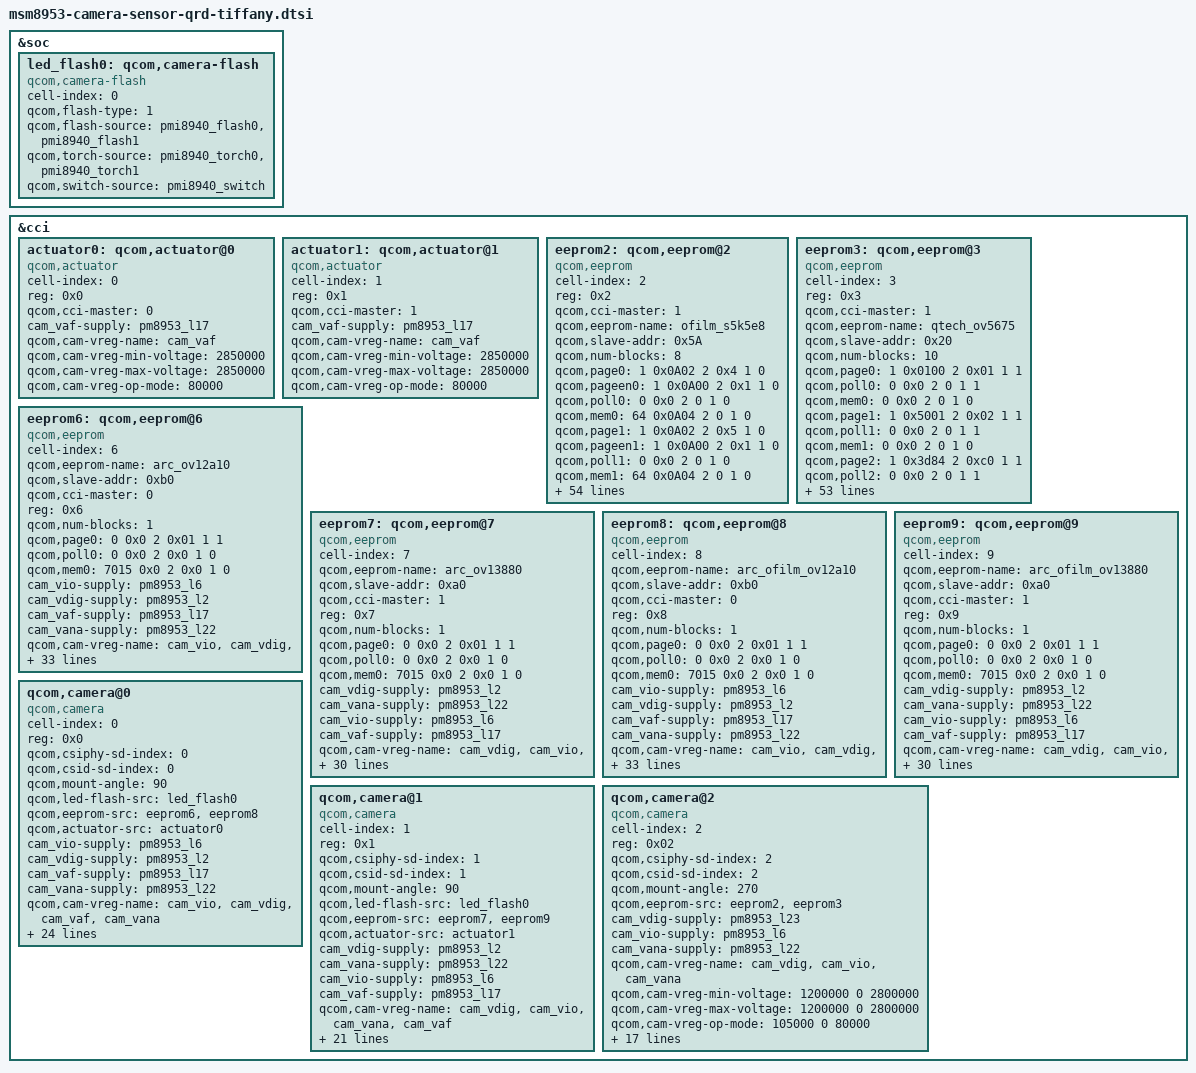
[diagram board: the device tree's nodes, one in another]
/*
 * Copyright (c) 2015-2016, The Linux Foundation. All rights reserved.
 * Copyright (C) 2019 XiaoMi, Inc.
 *
 * This program is free software; you can redistribute it and/or modify
 * it under the terms of the GNU General Public License version 2 and
 * only version 2 as published by the Free Software Foundation.
 *
 * This program is distributed in the hope that it will be useful,
 * but WITHOUT ANY WARRANTY; without even the implied warranty of
 * MERCHANTABILITY or FITNESS FOR A PARTICULAR PURPOSE.  See the
 * GNU General Public License for more details.
 */

&soc {
	led_flash0: qcom,camera-flash {
		cell-index = <0>;
		compatible = "qcom,camera-flash";
		qcom,flash-type = <1>;
		qcom,flash-source = <&pmi8940_flash0 &pmi8940_flash1>;
		qcom,torch-source = <&pmi8940_torch0 &pmi8940_torch1>;
		qcom,switch-source = <&pmi8940_switch>;
	};
};

&cci {
	actuator0: qcom,actuator@0 {
		cell-index = <0>;
		reg = <0x0>;
		compatible = "qcom,actuator";
		qcom,cci-master = <0>;
		cam_vaf-supply = <&pm8953_l17>;
		qcom,cam-vreg-name = "cam_vaf";
		qcom,cam-vreg-min-voltage = <2850000>;
		qcom,cam-vreg-max-voltage = <2850000>;
		qcom,cam-vreg-op-mode = <80000>;
	};

	actuator1: qcom,actuator@1 {
		cell-index = <1>;
		reg = <0x1>;
		compatible = "qcom,actuator";
		qcom,cci-master = <1>;
		cam_vaf-supply = <&pm8953_l17>;
		qcom,cam-vreg-name = "cam_vaf";
		qcom,cam-vreg-min-voltage = <2850000>;
		qcom,cam-vreg-max-voltage = <2850000>;
		qcom,cam-vreg-op-mode = <80000>;
	};


	eeprom2: qcom,eeprom@2 {
		cell-index = <2>;
		reg = <0x2>;
		compatible = "qcom,eeprom";
		qcom,cci-master = <1>;

		qcom,eeprom-name = "ofilm_s5k5e8";
		qcom,slave-addr = <0x5A>;
		qcom,num-blocks = <8>;

		qcom,page0 = <1 0x0A02 2 0x4 1 0>;
		qcom,pageen0 = <1 0x0A00 2 0x1 1 0>;
		qcom,poll0 = <0 0x0 2 0 1 0>;
		qcom,mem0 = <64 0x0A04 2 0 1 0>;

		qcom,page1 = <1 0x0A02 2 0x5 1 0>;
		qcom,pageen1 = <1 0x0A00 2 0x1 1 0>;
		qcom,poll1 = <0 0x0 2 0 1 0>;
		qcom,mem1 = <64 0x0A04 2 0 1 0>;

		qcom,page2 = <1 0x0A02 2 0x6 1 0>;
		qcom,pageen2 = <1 0x0A00 2 0x1 1 0>;
		qcom,poll2 = <0 0x0 2 0 1 0>;
		qcom,mem2 = <64 0x0A04 2 0 1 0>;

		qcom,page3 = <1 0x0A02 2 0x7 1 0>;
		qcom,pageen3 = <1 0x0A00 2 0x1 1 0>;
		qcom,poll3 = <0 0x0 2 0 1 0>;
		qcom,mem3 = <64 0x0A04 2 0 1 0>;

		qcom,page4 = <1 0x0A02 2 0x8 1 0>;
		qcom,pageen4 = <1 0x0A00 2 0x1 1 0>;
		qcom,poll4 = <0 0x0 2 0 1 0>;
		qcom,mem4 = <64 0x0A04 2 0 1 0>;

		qcom,page5 = <1 0x0A02 2 0x9 1 0>;
		qcom,pageen5 = <1 0x0A00 2 0x1 1 0>;
		qcom,poll5 = <0 0x0 2 0 1 0>;
		qcom,mem5 = <64 0x0A04 2 0 1 0>;

		qcom,page6 = <1 0x0A02 2 0xA 1 0>;
		qcom,pageen6 = <1 0x0A00 2 0x1 1 0>;
		qcom,poll6 = <0 0x0 2 0 1 0>;
		qcom,mem6 = <64 0x0A04 2 0 1 0>;

		qcom,page7 = <1 0x0A02 2 0xE 1 0>;
		qcom,pageen7 = <1 0x0A00 2 0x1 1 0>;
		qcom,poll7 = <0 0x0 2 0 1 0>;
		qcom,mem7 = <2 0x0A04 2 0 1 0>;

		cam_vdig-supply = <&pm8953_l23>;
		cam_vana-supply = <&pm8953_l22>;
		cam_vio-supply = <&pm8953_l6>;
		qcom,cam-vreg-name = "cam_vdig", "cam_vio", "cam_vana";
		qcom,cam-vreg-min-voltage = <1200000 0 2800000>;
		qcom,cam-vreg-max-voltage = <1200000 0 2800000>;
		qcom,cam-vreg-op-mode = <105000 0 80000>;
		qcom,gpio-no-mux = <0>;
		pinctrl-names = "cam_default", "cam_suspend";
		pinctrl-0 = <&cam_sensor_mclk1_default
						&cam_sensor_front1_default>;
		pinctrl-1 = <&cam_sensor_mclk1_sleep &cam_sensor_front1_sleep>;
		gpios = <&tlmm 27 0>,
			<&tlmm 129 0>;
		qcom,gpio-reset = <1>;
		qcom,gpio-req-tbl-num = <0 1>;
		qcom,gpio-req-tbl-flags = <1 0>;
		qcom,gpio-req-tbl-label = "CAMIF_MCLK2",
					  "CAM_RESET2";
		qcom,cam-power-seq-type = "sensor_gpio", "sensor_vreg",
			"sensor_vreg", "sensor_vreg", "sensor_clk" , "sensor_gpio";
		qcom,cam-power-seq-val = "sensor_gpio_reset", "cam_vana",
			"cam_vdig",	"cam_vio", "sensor_cam_mclk", "sensor_gpio_reset";
		qcom,cam-power-seq-cfg-val = <0 1 1 1 24000000 1>;
		qcom,cam-power-seq-delay = <1 0 0 0 10 1>;

		status = "ok";
		clocks = <&clock_gcc clk_mclk1_clk_src>,
			<&clock_gcc clk_gcc_camss_mclk1_clk>;
		clock-names = "cam_src_clk", "cam_clk";
		qcom,clock-rates = <24000000 0>;
	};


	eeprom3: qcom,eeprom@3 {
		cell-index = <3>;
		reg = <0x3>;
		compatible = "qcom,eeprom";
		qcom,cci-master = <1>;

		qcom,eeprom-name = "qtech_ov5675";
		qcom,slave-addr = <0x20>;

		qcom,num-blocks = <10>;
		qcom,page0 = <1 0x0100 2 0x01 1 1>;
		qcom,poll0 = <0 0x0 2 0 1 1>;
		qcom,mem0 = <0 0x0 2 0 1 0>;

		qcom,page1 = <1 0x5001 2 0x02 1 1>;
		qcom,poll1 = <0 0x0 2 0 1 1>;
		qcom,mem1 = <0 0x0 2 0 1 0>;

		qcom,page2 = <1 0x3d84 2 0xc0 1 1>;
		qcom,poll2 = <0 0x0 2 0 1 1>;
		qcom,mem2 = <0 0x0 2 0 1 0>;

		qcom,page3 = <1 0x3d88 2 0x70 1 1>;
		qcom,poll3 = <0 0x0 2 0 1 1>;
		qcom,mem3 = <0 0x0 2 0 1 0>;

		qcom,page4 = <1 0x3d89 2 0x10 1 1>;
		qcom,poll4 = <0 0x0 2 0 1 1>;
		qcom,mem4 = <0 0x0 2 0 1 0>;

		qcom,page5 = <1 0x3d8a 2 0x70 1 0>;
		qcom,poll5 = <0 0x0 2 0 1 1>;
		qcom,mem5 = <0 0x0 2 0 1 0>;

		qcom,page6 = <1 0x3d8b 2 0x29 1 10>;
		qcom,poll6 = <0 0x0 2 0 1 1>;
		qcom,mem6 = <0 0x0 2 0 1 0>;

		qcom,page7 = <1 0x3d81 2 0x01 1 10>;
		qcom,poll7 = <0 0x0 2 0 1 1>;
		qcom,mem7 = <0 0x0 2 0 1 0>;

		qcom,page8 = <0 0x0 2 0 1 0>;
		qcom,poll8 = <0 0x0 2 0 1 1>;
		qcom,mem8 = <40 0x7010 2 0 1 5>;

		qcom,page9 = <1 0x5001 2 0x03 1 5>;
		qcom,pageen9 = <1 0x0100 2 0x00 1 5>;
		qcom,poll9 = <0 0x0 2 0 1 1>;
		qcom,mem9 = <0 0x0 2 0 1 0>;

		cam_vdig-supply = <&pm8953_l23>;
		cam_vana-supply = <&pm8953_l22>;
		cam_vio-supply = <&pm8953_l6>;
		qcom,cam-vreg-name = "cam_vdig", "cam_vio", "cam_vana";
		qcom,cam-vreg-min-voltage = <1200000 0 2800000>;
		qcom,cam-vreg-max-voltage = <1200000 0 2800000>;
		qcom,cam-vreg-op-mode = <105000 0 80000>;
		qcom,gpio-no-mux = <0>;
		pinctrl-names = "cam_default", "cam_suspend";
		pinctrl-0 = <&cam_sensor_mclk1_default
						&cam_sensor_front1_default>;
		pinctrl-1 = <&cam_sensor_mclk1_sleep &cam_sensor_front1_sleep>;
		gpios = <&tlmm 27 0>,
			<&tlmm 129 0>;
		qcom,gpio-reset = <1>;
		qcom,gpio-req-tbl-num = <0 1>;
		qcom,gpio-req-tbl-flags = <1 0>;
		qcom,gpio-req-tbl-label = "CAMIF_MCLK2",
					  "CAM_RESET2";
		qcom,cam-power-seq-type = "sensor_gpio", "sensor_vreg",
			"sensor_vreg", "sensor_vreg", "sensor_clk" , "sensor_gpio";
		qcom,cam-power-seq-val = "sensor_gpio_reset", "cam_vana",
			"cam_vdig",	"cam_vio", "sensor_cam_mclk", "sensor_gpio_reset";
		qcom,cam-power-seq-cfg-val = <0 1 1 1 24000000 1>;
		qcom,cam-power-seq-delay = <1 0 0 0 10 1>;

		status = "ok";
		clocks = <&clock_gcc clk_mclk1_clk_src>,
			<&clock_gcc clk_gcc_camss_mclk1_clk>;
		clock-names = "cam_src_clk", "cam_clk";
		qcom,clock-rates = <24000000 0>;
	};

	eeprom6: qcom,eeprom@6 {
		cell-index = <6>;
		qcom,eeprom-name = "arc_ov12a10";
		compatible = "qcom,eeprom";
		qcom,slave-addr = <0xb0>;
		qcom,cci-master = <0>;
		reg = <0x6>;
		qcom,num-blocks = <1>;
		qcom,page0 = <0 0x0 2 0x01 1 1>;
		qcom,poll0 = <0 0x0 2 0x0 1 0>;
		qcom,mem0 = <7015 0x0 2 0x0 1 0>;

		cam_vio-supply = <&pm8953_l6>;
		cam_vdig-supply = <&pm8953_l2>;
		cam_vaf-supply = <&pm8953_l17>;
		cam_vana-supply = <&pm8953_l22>;
		qcom,cam-vreg-name = "cam_vio", "cam_vdig", "cam_vaf",
						"cam_vana";
		qcom,cam-vreg-min-voltage = <0 1100000 2850000 2800000>;
		qcom,cam-vreg-max-voltage = <0 1200000 2850000 2800000>;
		qcom,cam-vreg-op-mode = <0 105000 100000 80000>;
		pinctrl-names = "cam_default", "cam_suspend";
		pinctrl-0 = <&cam_sensor_mclk0_default
				&cam_sensor_rear_default
				&cam_sensor_rear_vana>;
		pinctrl-1 = <&cam_sensor_mclk0_sleep &cam_sensor_rear_sleep
				&cam_sensor_rear_vana_sleep>;
		gpios = <&tlmm 26 0>,
			<&tlmm 33 0>,
			<&tlmm 62 0>;
		qcom,gpio-reset = <1>;
		qcom,gpio-vana = <2>;
		qcom,gpio-req-tbl-num = <0 1 2>;
		qcom,gpio-req-tbl-flags = <1 0 0>;
		qcom,gpio-req-tbl-label = "CAMIF_MCLK0",
			"CAM_RESET0",
			"CAM_VANA";
		qcom,cam-power-seq-type = "sensor_gpio", "sensor_gpio", "sensor_vreg",
			"sensor_vreg", "sensor_vreg", "sensor_vreg", "sensor_clk" , "sensor_gpio", "sensor_gpio";
		qcom,cam-power-seq-val = "sensor_gpio_reset", "sensor_gpio_standby", "cam_vana",
			"cam_vdig",	"cam_vio", "cam_vaf", "sensor_cam_mclk", "sensor_gpio_reset", "sensor_gpio_standby";
		qcom,cam-power-seq-cfg-val = <0 0 1 1 1 1 24000000 1 1>;
		qcom,cam-power-seq-delay = <1 1 0 0 0 0 10 1 1>;
		status = "ok";
		clocks = <&clock_gcc clk_mclk0_clk_src>,
				<&clock_gcc clk_gcc_camss_mclk0_clk>;
		clock-names = "cam_src_clk", "cam_clk";
		qcom,clock-rates = <24000000 0>;
	};
	eeprom7: qcom,eeprom@7 {
		cell-index = <7>;
		qcom,eeprom-name = "arc_ov13880";
		compatible = "qcom,eeprom";
		qcom,slave-addr = <0xa0>;
		qcom,cci-master = <1>;
		reg = <0x7>;
		qcom,num-blocks = <1>;
		qcom,page0 = <0 0x0 2 0x01 1 1>;
		qcom,poll0 = <0 0x0 2 0x0 1 0>;
		qcom,mem0 = <7015 0x0 2 0x0 1 0>;
		cam_vdig-supply = <&pm8953_l2>;
		cam_vana-supply = <&pm8953_l22>;
		cam_vio-supply = <&pm8953_l6>;
		cam_vaf-supply = <&pm8953_l17>;
		qcom,cam-vreg-name = "cam_vdig", "cam_vio", "cam_vana",
							"cam_vaf";
		qcom,cam-vreg-min-voltage = <1200000 0 2800000 2850000>;
		qcom,cam-vreg-max-voltage = <1200000 0 2800000 2850000>;
		qcom,cam-vreg-op-mode = <200000 0 80000 100000>;
		pinctrl-names = "cam_default", "cam_suspend";
		pinctrl-0 = <&cam_sensor_mclk2_default
				&cam_sensor_front_default>;
		pinctrl-1 = <&cam_sensor_mclk2_sleep
				&cam_sensor_front_sleep>;
		gpios = <&tlmm 28 0>,
			<&tlmm 41 0>;
		qcom,gpio-reset = <1>;
		qcom,gpio-req-tbl-num = <0 1>;
		qcom,gpio-req-tbl-flags = <1 0>;
		qcom,gpio-req-tbl-label = "CAMIF_MCLK1",
			"CAM_RESET1";
		qcom,cam-power-seq-type = "sensor_gpio", "sensor_gpio", "sensor_vreg",
			"sensor_vreg", "sensor_vreg", "sensor_vreg", "sensor_clk" , "sensor_gpio", "sensor_gpio";
		qcom,cam-power-seq-val = "sensor_gpio_reset", "sensor_gpio_standby", "cam_vana",
			"cam_vdig",	"cam_vio", "cam_vaf", "sensor_cam_mclk", "sensor_gpio_reset", "sensor_gpio_standby";
		qcom,cam-power-seq-cfg-val = <0 0 1 1 1 1 24000000 1 1>;
		qcom,cam-power-seq-delay = <1 1 0 0 0 0 10 1 1>;
		status = "ok";
		clocks = <&clock_gcc clk_mclk2_clk_src>,
				<&clock_gcc clk_gcc_camss_mclk2_clk>;
		clock-names = "cam_src_clk", "cam_clk";
		qcom,clock-rates = <24000000 0>;
	};

	eeprom8: qcom,eeprom@8 {
		cell-index = <8>;
		qcom,eeprom-name = "arc_ofilm_ov12a10";
		compatible = "qcom,eeprom";
		qcom,slave-addr = <0xb0>;
		qcom,cci-master = <0>;
		reg = <0x8>;
		qcom,num-blocks = <1>;
		qcom,page0 = <0 0x0 2 0x01 1 1>;
		qcom,poll0 = <0 0x0 2 0x0 1 0>;
		qcom,mem0 = <7015 0x0 2 0x0 1 0>;

		cam_vio-supply = <&pm8953_l6>;
		cam_vdig-supply = <&pm8953_l2>;
		cam_vaf-supply = <&pm8953_l17>;
		cam_vana-supply = <&pm8953_l22>;
		qcom,cam-vreg-name = "cam_vio", "cam_vdig", "cam_vaf",
						"cam_vana";
		qcom,cam-vreg-min-voltage = <0 1100000 2850000 2800000>;
		qcom,cam-vreg-max-voltage = <0 1200000 2850000 2800000>;
		qcom,cam-vreg-op-mode = <0 105000 100000 80000>;
		pinctrl-names = "cam_default", "cam_suspend";
		pinctrl-0 = <&cam_sensor_mclk0_default
				&cam_sensor_rear_default
				&cam_sensor_rear_vana>;
		pinctrl-1 = <&cam_sensor_mclk0_sleep &cam_sensor_rear_sleep
				&cam_sensor_rear_vana_sleep>;
		gpios = <&tlmm 26 0>,
			<&tlmm 33 0>,
			<&tlmm 62 0>;
		qcom,gpio-reset = <1>;
		qcom,gpio-vana = <2>;
		qcom,gpio-req-tbl-num = <0 1 2>;
		qcom,gpio-req-tbl-flags = <1 0 0>;
		qcom,gpio-req-tbl-label = "CAMIF_MCLK0",
			"CAM_RESET0",
			"CAM_VANA";
		qcom,cam-power-seq-type = "sensor_gpio", "sensor_gpio", "sensor_vreg",
			"sensor_vreg", "sensor_vreg", "sensor_vreg", "sensor_clk" , "sensor_gpio", "sensor_gpio";
		qcom,cam-power-seq-val = "sensor_gpio_reset", "sensor_gpio_standby", "cam_vana",
			"cam_vdig",	"cam_vio", "cam_vaf", "sensor_cam_mclk", "sensor_gpio_reset", "sensor_gpio_standby";
		qcom,cam-power-seq-cfg-val = <0 0 1 1 1 1 24000000 1 1>;
		qcom,cam-power-seq-delay = <1 1 0 0 0 0 10 1 1>;
		status = "ok";
		clocks = <&clock_gcc clk_mclk0_clk_src>,
				<&clock_gcc clk_gcc_camss_mclk0_clk>;
		clock-names = "cam_src_clk", "cam_clk";
		qcom,clock-rates = <24000000 0>;
	};
	eeprom9: qcom,eeprom@9 {
		cell-index = <9>;
		qcom,eeprom-name = "arc_ofilm_ov13880";
		compatible = "qcom,eeprom";
		qcom,slave-addr = <0xa0>;
		qcom,cci-master = <1>;
		reg = <0x9>;
		qcom,num-blocks = <1>;
		qcom,page0 = <0 0x0 2 0x01 1 1>;
		qcom,poll0 = <0 0x0 2 0x0 1 0>;
		qcom,mem0 = <7015 0x0 2 0x0 1 0>;
		cam_vdig-supply = <&pm8953_l2>;
		cam_vana-supply = <&pm8953_l22>;
		cam_vio-supply = <&pm8953_l6>;
		cam_vaf-supply = <&pm8953_l17>;
		qcom,cam-vreg-name = "cam_vdig", "cam_vio", "cam_vana",
							"cam_vaf";
		qcom,cam-vreg-min-voltage = <1200000 0 2800000 2850000>;
		qcom,cam-vreg-max-voltage = <1200000 0 2800000 2850000>;
		qcom,cam-vreg-op-mode = <200000 0 80000 100000>;
		pinctrl-names = "cam_default", "cam_suspend";
		pinctrl-0 = <&cam_sensor_mclk2_default
				&cam_sensor_front_default>;
		pinctrl-1 = <&cam_sensor_mclk2_sleep
				&cam_sensor_front_sleep>;
		gpios = <&tlmm 28 0>,
			<&tlmm 41 0>;
		qcom,gpio-reset = <1>;
		qcom,gpio-req-tbl-num = <0 1>;
		qcom,gpio-req-tbl-flags = <1 0>;
		qcom,gpio-req-tbl-label = "CAMIF_MCLK1",
			"CAM_RESET1";
		qcom,cam-power-seq-type = "sensor_gpio", "sensor_gpio", "sensor_vreg",
			"sensor_vreg", "sensor_vreg", "sensor_vreg", "sensor_clk" , "sensor_gpio", "sensor_gpio";
		qcom,cam-power-seq-val = "sensor_gpio_reset", "sensor_gpio_standby", "cam_vana",
			"cam_vdig",	"cam_vio", "cam_vaf", "sensor_cam_mclk", "sensor_gpio_reset", "sensor_gpio_standby";
		qcom,cam-power-seq-cfg-val = <0 0 1 1 1 1 24000000 1 1>;
		qcom,cam-power-seq-delay = <1 1 0 0 0 0 10 1 1>;
		status = "ok";
		clocks = <&clock_gcc clk_mclk2_clk_src>,
				<&clock_gcc clk_gcc_camss_mclk2_clk>;
		clock-names = "cam_src_clk", "cam_clk";
		qcom,clock-rates = <24000000 0>;
	};

	qcom,camera@0 {
		cell-index = <0>;
		compatible = "qcom,camera";
		reg = <0x0>;
		qcom,csiphy-sd-index = <0>;
		qcom,csid-sd-index = <0>;
		qcom,mount-angle = <90>;
		qcom,led-flash-src = <&led_flash0>;
		//qcom,eeprom-src = <&eeprom0 &eeprom4 &eeprom6 &eeprom8>;
		qcom,eeprom-src = <&eeprom6 &eeprom8>;
		qcom,actuator-src = <&actuator0>;
		cam_vio-supply = <&pm8953_l6>;
		cam_vdig-supply = <&pm8953_l2>;
		cam_vaf-supply = <&pm8953_l17>;
		cam_vana-supply = <&pm8953_l22>;
		qcom,cam-vreg-name = "cam_vio", "cam_vdig", "cam_vaf",
						"cam_vana";
		qcom,cam-vreg-min-voltage = <0 1100000 2850000 2800000>;
		qcom,cam-vreg-max-voltage = <0 1200000 2850000 2800000>;
		qcom,cam-vreg-op-mode = <0 105000 100000 80000>;
		pinctrl-names = "cam_default", "cam_suspend";
		pinctrl-0 = <&cam_sensor_mclk0_default
				&cam_sensor_rear_default
				&cam_sensor_rear_vana>;
		pinctrl-1 = <&cam_sensor_mclk0_sleep
				&cam_sensor_rear_sleep
				&cam_sensor_rear_vana_sleep>;
		gpios = <&tlmm 26 0>,
			<&tlmm 33 0>,
			<&tlmm 62 0>;
		qcom,gpio-reset = <1>;
		qcom,gpio-vana = <2>;
		qcom,gpio-req-tbl-num = <0 1 2>;
		qcom,gpio-req-tbl-flags = <1 0 0>;
		qcom,gpio-req-tbl-label = "CAMIF_MCLK0",
			"CAM_RESET0",
			"CAM_VANA";
		qcom,sensor-position = <0>;
		qcom,sensor-mode = <0>;
		qcom,cci-master = <0>;
		status = "ok";
		clocks = <&clock_gcc clk_mclk0_clk_src>,
			<&clock_gcc clk_gcc_camss_mclk0_clk>;
		clock-names = "cam_src_clk", "cam_clk";
		qcom,clock-rates = <24000000 0>;
	};

	qcom,camera@1 {
		cell-index = <1>;
		compatible = "qcom,camera";
		reg = <0x1>;
		qcom,csiphy-sd-index = <1>;
		qcom,csid-sd-index = <1>;
		qcom,mount-angle = <90>;
		qcom,led-flash-src = <&led_flash0>;
		//qcom,eeprom-src = <&eeprom1 &eeprom5 &eeprom7 &eeprom9>;
		qcom,eeprom-src = <&eeprom7 &eeprom9>;
		qcom,actuator-src = <&actuator1>;
		cam_vdig-supply = <&pm8953_l2>;
		cam_vana-supply = <&pm8953_l22>;
		cam_vio-supply = <&pm8953_l6>;
		cam_vaf-supply = <&pm8953_l17>;
		qcom,cam-vreg-name = "cam_vdig", "cam_vio", "cam_vana",
							"cam_vaf";
		qcom,cam-vreg-min-voltage = <1200000 0 2800000 2850000>;
		qcom,cam-vreg-max-voltage = <1200000 0 2800000 2850000>;
		qcom,cam-vreg-op-mode = <200000 0 80000 100000>;
		pinctrl-names = "cam_default", "cam_suspend";
		pinctrl-0 = <&cam_sensor_mclk2_default
				&cam_sensor_front_default>;
		pinctrl-1 = <&cam_sensor_mclk2_sleep
				&cam_sensor_front_sleep>;
		gpios = <&tlmm 28 0>,
			<&tlmm 41 0>;
		qcom,gpio-reset = <1>;
		qcom,gpio-req-tbl-num = <0 1>;
		qcom,gpio-req-tbl-flags = <1 0>;
		qcom,gpio-req-tbl-label = "CAMIF_MCLK1",
			"CAM_RESET1";
		qcom,sensor-position = <0>;
		qcom,sensor-mode = <0>;
		qcom,cci-master = <1>;
		status = "ok";
		clocks = <&clock_gcc clk_mclk2_clk_src>,
			<&clock_gcc clk_gcc_camss_mclk2_clk>;
		clock-names = "cam_src_clk", "cam_clk";
		qcom,clock-rates = <24000000 0>;
	};

	qcom,camera@2 {
		cell-index = <2>;
		compatible = "qcom,camera";
		reg = <0x02>;
		qcom,csiphy-sd-index = <2>;
		qcom,csid-sd-index = <2>;
		qcom,mount-angle = <270>;
		qcom,eeprom-src = <&eeprom2 &eeprom3>;
		cam_vdig-supply = <&pm8953_l23>;
		cam_vio-supply = <&pm8953_l6>;
		cam_vana-supply = <&pm8953_l22>;
		qcom,cam-vreg-name = "cam_vdig", "cam_vio", "cam_vana";
		qcom,cam-vreg-min-voltage = <1200000 0 2800000>;
		qcom,cam-vreg-max-voltage = <1200000 0 2800000>;
		qcom,cam-vreg-op-mode = <105000 0 80000>;
		qcom,gpio-no-mux = <0>;
		pinctrl-names = "cam_default", "cam_suspend";
		pinctrl-0 = <&cam_sensor_mclk1_default
				&cam_sensor_front1_default>;
		pinctrl-1 = <&cam_sensor_mclk1_sleep
				&cam_sensor_front1_sleep>;
		gpios = <&tlmm 27 0>,
			<&tlmm 129 0>;
		qcom,gpio-reset = <1>;
		qcom,gpio-req-tbl-num = <0 1>;
		qcom,gpio-req-tbl-flags = <1 0>;
		qcom,gpio-req-tbl-label = "CAMIF_MCLK2",
					  "CAM_RESET2";
		qcom,sensor-position = <1>;
		qcom,sensor-mode = <0>;
		qcom,cci-master = <1>;
		status = "ok";
		clocks = <&clock_gcc clk_mclk1_clk_src>,
			<&clock_gcc clk_gcc_camss_mclk1_clk>;
		clock-names = "cam_src_clk", "cam_clk";
		qcom,clock-rates = <24000000 0>;
	};
};
